AUTOSAR XML (schema 4.0)
package /HVACControlComponent
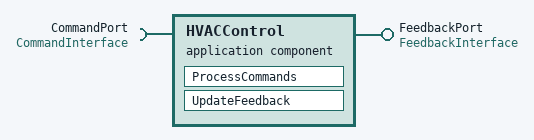
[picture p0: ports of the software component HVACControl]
  application software component type HVACControl
    provide port FeedbackPort: required-interface=FeedbackInterface
    require port CommandPort: provided-interface=CommandInterface
    internal behavior HVACControlBehavior
      runnable ProcessCommands
      runnable UpdateFeedback
